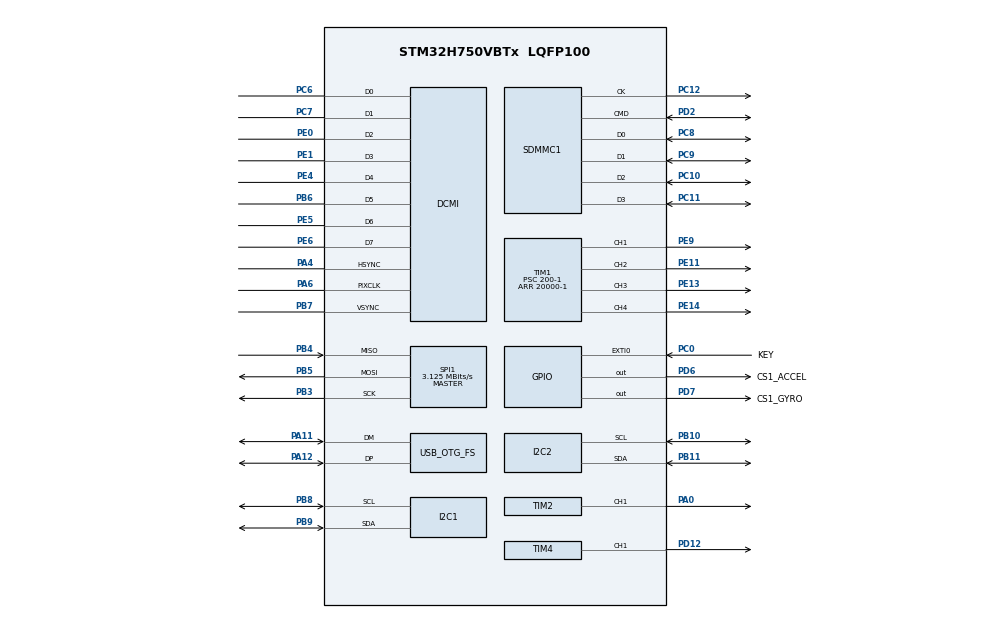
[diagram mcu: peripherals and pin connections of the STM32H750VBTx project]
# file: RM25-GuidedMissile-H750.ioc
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CORTEX_M7.AccessPermission-Cortex_Memory_Protection_Unit_Region0_Settings=MPU_REGION_FULL_ACCESS
CORTEX_M7.BaseAddress-Cortex_Memory_Protection_Unit_Region0_Settings=0x24000000
CORTEX_M7.CPU_DCache=Enabled
CORTEX_M7.CPU_ICache=Enabled
CORTEX_M7.Enable-Cortex_Memory_Protection_Unit_Region0_Settings=MPU_REGION_ENABLE
CORTEX_M7.Enable-Cortex_Memory_Protection_Unit_Region1_Settings=__NULL
CORTEX_M7.Enable-Cortex_Memory_Protection_Unit_Region2_Settings=__NULL
CORTEX_M7.IsBufferable-Cortex_Memory_Protection_Unit_Region0_Settings=MPU_ACCESS_BUFFERABLE
CORTEX_M7.IsCacheable-Cortex_Memory_Protection_Unit_Region0_Settings=MPU_ACCESS_CACHEABLE
CORTEX_M7.IsShareable-Cortex_Memory_Protection_Unit_Region0_Settings=MPU_ACCESS_NOT_SHAREABLE
CORTEX_M7.MPU_Control=MPU_PRIVILEGED_DEFAULT
CORTEX_M7.Size-Cortex_Memory_Protection_Unit_Region0_Settings=MPU_REGION_SIZE_256KB
DCMI.JPEGMode=DCMI_JPEG_DISABLE
Dma.DCMI.0.Direction=DMA_PERIPH_TO_MEMORY
Dma.DCMI.0.EventEnable=DISABLE
Dma.DCMI.0.FIFOMode=DMA_FIFOMODE_ENABLE
Dma.DCMI.0.FIFOThreshold=DMA_FIFO_THRESHOLD_FULL
Dma.DCMI.0.Instance=DMA1_Stream0
Dma.DCMI.0.MemBurst=DMA_MBURST_SINGLE
Dma.DCMI.0.MemDataAlignment=DMA_MDATAALIGN_HALFWORD
Dma.DCMI.0.MemInc=DMA_MINC_ENABLE
Dma.DCMI.0.Mode=DMA_CIRCULAR
Dma.DCMI.0.PeriphBurst=DMA_PBURST_SINGLE
Dma.DCMI.0.PeriphDataAlignment=DMA_PDATAALIGN_WORD
Dma.DCMI.0.PeriphInc=DMA_PINC_DISABLE
Dma.DCMI.0.Polarity=HAL_DMAMUX_REQ_GEN_RISING
Dma.DCMI.0.Priority=DMA_PRIORITY_LOW
Dma.DCMI.0.RequestNumber=1
Dma.DCMI.0.SignalID=NONE
Dma.DCMI.0.SyncEnable=DISABLE
Dma.DCMI.0.SyncPolarity=HAL_DMAMUX_SYNC_NO_EVENT
Dma.DCMI.0.SyncRequestNumber=1
Dma.DCMI.0.SyncSignalID=NONE
Dma.Request0=DCMI
Dma.Request1=TIM2_CH1
Dma.TIM2_CH1.1.Direction=DMA_MEMORY_TO_PERIPH
Dma.TIM2_CH1.1.EventEnable=DISABLE
Dma.TIM2_CH1.1.FIFOMode=DMA_FIFOMODE_DISABLE
Dma.TIM2_CH1.1.Instance=DMA1_Stream1
Dma.TIM2_CH1.1.MemDataAlignment=DMA_MDATAALIGN_WORD
Dma.TIM2_CH1.1.MemInc=DMA_MINC_ENABLE
Dma.TIM2_CH1.1.Mode=DMA_NORMAL
Dma.TIM2_CH1.1.PeriphDataAlignment=DMA_PDATAALIGN_WORD
Dma.TIM2_CH1.1.PeriphInc=DMA_PINC_DISABLE
Dma.TIM2_CH1.1.Polarity=HAL_DMAMUX_REQ_GEN_RISING
Dma.TIM2_CH1.1.Priority=DMA_PRIORITY_LOW
Dma.TIM2_CH1.1.RequestNumber=1
Dma.TIM2_CH1.1.SignalID=NONE
Dma.TIM2_CH1.1.SyncEnable=DISABLE
Dma.TIM2_CH1.1.SyncPolarity=HAL_DMAMUX_SYNC_NO_EVENT
Dma.TIM2_CH1.1.SyncRequestNumber=1
Dma.TIM2_CH1.1.SyncSignalID=NONE
FATFS.USE_DMA_CODE_SD=1
I2C1.Timing=0x10C0ECFF
I2C2.Timing=0x10C0ECFF
Mcu.Family=STM32H7
Mcu.Name=STM32H750VBTx
Mcu.Package=LQFP100
Mdma.MDMA_Channel0.Request0=SDMMC1_END_DATA
Mdma.MDMA_Channel0.RequestsNb=1
Mdma.MDMA_Channel0.SDMMC1_END_DATA.0.BlockCount=0
Mdma.MDMA_Channel0.SDMMC1_END_DATA.0.BlockDataLength=0
Mdma.MDMA_Channel0.SDMMC1_END_DATA.0.BufferTransferLength=1
Mdma.MDMA_Channel0.SDMMC1_END_DATA.0.CircularMode=MDMA_LINEAR_LIST
Mdma.MDMA_Channel0.SDMMC1_END_DATA.0.DataAlignment=MDMA_DATAALIGN_PACKENABLE
Mdma.MDMA_Channel0.SDMMC1_END_DATA.0.DestBlockAddressOffset=0
Mdma.MDMA_Channel0.SDMMC1_END_DATA.0.DestBurst=MDMA_DEST_BURST_SINGLE
Mdma.MDMA_Channel0.SDMMC1_END_DATA.0.DestDataSize=MDMA_DEST_DATASIZE_BYTE
Mdma.MDMA_Channel0.SDMMC1_END_DATA.0.DestinationInc=MDMA_DEST_INC_BYTE
Mdma.MDMA_Channel0.SDMMC1_END_DATA.0.DstAddress=0
Mdma.MDMA_Channel0.SDMMC1_END_DATA.0.Endianness=MDMA_LITTLE_ENDIANNESS_PRESERVE
Mdma.MDMA_Channel0.SDMMC1_END_DATA.0.Instance=MDMA_Channel0
Mdma.MDMA_Channel0.SDMMC1_END_DATA.0.MaskAddress=0
Mdma.MDMA_Channel0.SDMMC1_END_DATA.0.MaskData=0
Mdma.MDMA_Channel0.SDMMC1_END_DATA.0.Priority=MDMA_PRIORITY_VERY_HIGH
Mdma.MDMA_Channel0.SDMMC1_END_DATA.0.Rank=First
Mdma.MDMA_Channel0.SDMMC1_END_DATA.0.SourceBlockAddressOffset=0
Mdma.MDMA_Channel0.SDMMC1_END_DATA.0.SourceBurst=MDMA_SOURCE_BURST_SINGLE
Mdma.MDMA_Channel0.SDMMC1_END_DATA.0.SourceDataSize=MDMA_SRC_DATASIZE_BYTE
Mdma.MDMA_Channel0.SDMMC1_END_DATA.0.SourceInc=MDMA_SRC_INC_BYTE
Mdma.MDMA_Channel0.SDMMC1_END_DATA.0.SrcAddress=0
Mdma.MDMA_Channel0.SDMMC1_END_DATA.0.TransferTriggerMode=MDMA_BUFFER_TRANSFER
Mdma.RequestSet0=MDMA_Channel0
Mdma.RequestSetsNb=1
NVIC.DCMI_IRQn=true\:6\:0\:true\:false\:true\:true\:true\:true
NVIC.DMA1_Stream0_IRQn=true\:7\:0\:true\:false\:true\:false\:true\:true
NVIC.DMA1_Stream1_IRQn=true\:0\:0\:false\:false\:true\:false\:true\:true
NVIC.EXTI0_IRQn=true\:5\:0\:true\:false\:true\:true\:true\:true
NVIC.MDMA_IRQn=true\:8\:0\:true\:false\:true\:true\:true\:true
NVIC.OTG_FS_IRQn=true\:0\:0\:true\:false\:true\:false\:true\:true
NVIC.PriorityGroup=NVIC_PRIORITYGROUP_4
NVIC.SDMMC1_IRQn=true\:9\:0\:true\:false\:true\:true\:true\:true
NVIC.TIM2_IRQn=true\:0\:0\:true\:false\:true\:true\:true\:true
NVIC.TIM6_DAC_IRQn=true\:10\:0\:true\:false\:true\:true\:true\:true
PA0.GPIO_PuPd=GPIO_NOPULL
PA0.GPIO_Speed=GPIO_SPEED_FREQ_VERY_HIGH
PA0.Signal=S_TIM2_CH1_ETR
PA11.Mode=Device_Only
PA11.Signal=USB_OTG_FS_DM
PA12.Mode=Device_Only
PA12.Signal=USB_OTG_FS_DP
PA13\ (JTMS/SWDIO).Mode=Serial_Wire
PA13\ (JTMS/SWDIO).Signal=DEBUG_JTMS-SWDIO
PA14\ (JTCK/SWCLK).Mode=Serial_Wire
PA14\ (JTCK/SWCLK).Signal=DEBUG_JTCK-SWCLK
PA4.Mode=Slave_8_bits_External_Synchro
PA4.Signal=DCMI_HSYNC
PA6.Mode=Slave_8_bits_External_Synchro
PA6.Signal=DCMI_PIXCLK
PB10.GPIO_Pu=GPIO_PULLUP
PB10.Mode=I2C
PB10.Signal=I2C2_SCL
PB11.GPIO_Pu=GPIO_PULLUP
PB11.Mode=I2C
PB11.Signal=I2C2_SDA
PB3\ (JTDO/TRACESWO).GPIO_PuPd=GPIO_PULLUP
PB3\ (JTDO/TRACESWO).GPIO_Speed=GPIO_SPEED_FREQ_MEDIUM
PB3\ (JTDO/TRACESWO).Mode=Full_Duplex_Master
PB3\ (JTDO/TRACESWO).Signal=SPI1_SCK
PB4\ (NJTRST).GPIO_PuPd=GPIO_PULLUP
PB4\ (NJTRST).GPIO_Speed=GPIO_SPEED_FREQ_MEDIUM
PB4\ (NJTRST).Mode=Full_Duplex_Master
PB4\ (NJTRST).Signal=SPI1_MISO
PB5.GPIO_PuPd=GPIO_PULLUP
PB5.GPIO_Speed=GPIO_SPEED_FREQ_MEDIUM
PB5.Mode=Full_Duplex_Master
PB5.Signal=SPI1_MOSI
PB6.Mode=Slave_8_bits_External_Synchro
PB6.Signal=DCMI_D5
PB7.Mode=Slave_8_bits_External_Synchro
PB7.Signal=DCMI_VSYNC
PB8.GPIO_Pu=GPIO_PULLUP
PB8.Mode=I2C
PB8.Signal=I2C1_SCL
PB9.GPIO_Pu=GPIO_PULLUP
PB9.Mode=I2C
PB9.Signal=I2C1_SDA
PC0.GPIO_Label=KEY
PC0.GPIO_ModeDefaultEXTI=GPIO_MODE_IT_RISING_FALLING
PC0.GPIO_PuPd=GPIO_PULLUP
PC0.Signal=GPXTI0
PC10.GPIO_PuPd=GPIO_PULLUP
PC10.Mode=SD_4_bits_Wide_bus
PC10.Signal=SDMMC1_D2
PC11.GPIO_PuPd=GPIO_PULLUP
PC11.Mode=SD_4_bits_Wide_bus
PC11.Signal=SDMMC1_D3
PC12.GPIO_PuPd=GPIO_PULLUP
PC12.GPIO_Speed_High_Default=GPIO_SPEED_FREQ_VERY_HIGH
PC12.Mode=SD_4_bits_Wide_bus
PC12.Signal=SDMMC1_CK
PC6.Mode=Slave_8_bits_External_Synchro
PC6.Signal=DCMI_D0
PC7.Mode=Slave_8_bits_External_Synchro
PC7.Signal=DCMI_D1
PC8.GPIO_PuPd=GPIO_PULLUP
PC8.GPIO_Speed_High_Default=GPIO_SPEED_FREQ_VERY_HIGH
PC8.Mode=SD_4_bits_Wide_bus
PC8.Signal=SDMMC1_D0
PC9.GPIO_PuPd=GPIO_PULLUP
PC9.Mode=SD_4_bits_Wide_bus
PC9.Signal=SDMMC1_D1
PD12.Signal=S_TIM4_CH1
PD14.Signal=S_TIM4_CH3
PD2.GPIO_PuPd=GPIO_PULLUP
PD2.GPIO_Speed_High_Default=GPIO_SPEED_FREQ_VERY_HIGH
PD2.Mode=SD_4_bits_Wide_bus
PD2.Signal=SDMMC1_CMD
PD6.GPIO_Label=CS1_ACCEL
PD6.GPIO_PuPd=GPIO_PULLUP
PD6.Signal=GPIO_Output
PD7.GPIO_Label=CS1_GYRO
PD7.GPIO_PuPd=GPIO_PULLUP
PD7.Signal=GPIO_Output
PE0.Mode=Slave_8_bits_External_Synchro
PE0.Signal=DCMI_D2
PE1.Mode=Slave_8_bits_External_Synchro
PE1.Signal=DCMI_D3
PE11.Signal=S_TIM1_CH2
PE13.Signal=S_TIM1_CH3
PE14.Signal=S_TIM1_CH4
PE4.Mode=Slave_8_bits_External_Synchro
PE4.Signal=DCMI_D4
PE5.Mode=Slave_8_bits_External_Synchro
PE5.Signal=DCMI_D6
PE6.Mode=Slave_8_bits_External_Synchro
PE6.Signal=DCMI_D7
PE9.Signal=S_TIM1_CH1
PH0-OSC_IN\ (PH0).Mode=HSE-External-Oscillator
PH0-OSC_IN\ (PH0).Signal=RCC_OSC_IN
PH1-OSC_OUT\ (PH1).Mode=HSE-External-Oscillator
PH1-OSC_OUT\ (PH1).Signal=RCC_OSC_OUT
ProjectManager.HeapSize=0x2000
ProjectManager.StackSize=0x2000
ProjectManager.TargetToolchain=MDK-ARM V5.32
RCC.ADCFreq_Value=24000000
RCC.APB1Freq_Value=100000000
RCC.APB2Freq_Value=100000000
RCC.APB3Freq_Value=100000000
RCC.APB4Freq_Value=100000000
RCC.CortexFreq_Value=400000000
RCC.D1PPRE=RCC_APB3_DIV2
RCC.D2PPRE1=RCC_APB1_DIV2
RCC.D2PPRE2=RCC_APB2_DIV2
RCC.D3PPRE=RCC_APB4_DIV2
RCC.DIVM1=5
RCC.DIVM2=25
RCC.DIVM3=25
RCC.DIVN1=160
RCC.DIVN2=48
RCC.DIVN3=192
RCC.DIVQ1=4
RCC.DIVQ3=4
RCC.DIVR2=1
RCC.HCLKFreq_Value=200000000
RCC.HPRE=RCC_HCLK_DIV2
RCC.PLL2FRACN=0
RCC.PLL3FRACN=0
RCC.PLLFRACN=0
RCC.PLLSourceVirtual=RCC_PLLSOURCE_HSE
RCC.SYSCLKFreq_VALUE=400000000
RCC.SYSCLKSource=RCC_SYSCLKSOURCE_PLLCLK
RCC.USBCLockSelection=RCC_USBCLKSOURCE_HSI48
RCC.USBFreq_Value=48000000
SDMMC1.ClockDiv=5
SH.S_TIM1_CH1.0=TIM1_CH1,PWM Generation1 CH1
SH.S_TIM1_CH2.0=TIM1_CH2,PWM Generation2 CH2
SH.S_TIM1_CH3.0=TIM1_CH3,PWM Generation3 CH3
SH.S_TIM1_CH4.0=TIM1_CH4,PWM Generation4 CH4
SH.S_TIM2_CH1_ETR.0=TIM2_CH1,PWM Generation1 CH1
SH.S_TIM4_CH1.0=TIM4_CH1,PWM Generation1 CH1
SH.S_TIM4_CH3.0=TIM4_CH3
SPI1.BaudRatePrescaler=SPI_BAUDRATEPRESCALER_64
SPI1.CLKPhase=SPI_PHASE_2EDGE
SPI1.CLKPolarity=SPI_POLARITY_HIGH
SPI1.CalculateBaudRate=3.125 MBits/s
SPI1.DataSize=SPI_DATASIZE_8BIT
SPI1.Direction=SPI_DIRECTION_2LINES
SPI1.Mode=SPI_MODE_MASTER
SPI1.VirtualType=VM_MASTER
TIM1.Channel-PWM\ Generation1\ CH1=TIM_CHANNEL_1
TIM1.Channel-PWM\ Generation2\ CH2=TIM_CHANNEL_2
TIM1.Channel-PWM\ Generation3\ CH3=TIM_CHANNEL_3
TIM1.Channel-PWM\ Generation4\ CH4=TIM_CHANNEL_4
TIM1.Period=20000-1
TIM1.Prescaler=200-1
TIM1.Pulse-PWM\ Generation1\ CH1=2000
TIM1.Pulse-PWM\ Generation2\ CH2=2000
TIM1.Pulse-PWM\ Generation3\ CH3=2000
TIM1.Pulse-PWM\ Generation4\ CH4=2000
TIM2.Channel-PWM\ Generation1\ CH1=TIM_CHANNEL_1
TIM2.Period=250-1
TIM2.Prescaler=0
TIM4.Channel-PWM\ Generation1\ CH1=TIM_CHANNEL_1
TIM6.Period=1000-1
TIM6.Prescaler=200-1
USB_DEVICE.CLASS_NAME_FS=CDC
USB_DEVICE.VirtualMode-CDC_FS=Cdc
USB_DEVICE.VirtualModeFS=Cdc_FS
USB_OTG_FS.VirtualMode=Device_Only
VP_FATFS_VS_SDIO.Mode=SDIO
VP_TIM1_VS_ClockSourceINT.Mode=Internal
VP_TIM2_VS_ClockSourceINT.Mode=Internal
VP_TIM4_VS_ClockSourceINT.Mode=Internal
VP_TIM6_VS_ClockSourceINT.Mode=Enable_Timer
VP_USB_DEVICE_VS_USB_DEVICE_CDC_FS.Mode=CDC_FS
board=custom

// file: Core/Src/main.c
/* USER CODE BEGIN Header */
/**
  ******************************************************************************
  * @file           : main.c
  * @brief          : Main program body
  ******************************************************************************
  * @attention
  *
  * Copyright (c) 2023 STMicroelectronics.
  * All rights reserved.
  *
  * This software is licensed under terms that can be found in the LICENSE file
  * in the root directory of this software component.
  * If no LICENSE file comes with this software, it is provided AS-IS.
  *
  ******************************************************************************
  */
/* USER CODE END Header */
#include "main.h"
#include "dcmi.h"
#include "dma.h"
#include "fatfs.h"
#include "i2c.h"
#include "mdma.h"
#include "sdmmc.h"
#include "spi.h"
#include "tim.h"
#include "usb_device.h"
#include "gpio.h"

/* USER CODE BEGIN Includes */
#include "missile.h"
/* USER CODE END Includes */

void SystemClock_Config(void);
static void MPU_Initialize(void);
static void MPU_Config(void);

int main(void)
{

  /* Enable I-Cache---------------------------------------------------------*/
  SCB_EnableICache();

  /* Enable D-Cache---------------------------------------------------------*/
  SCB_EnableDCache();

  /* MCU Configuration--------------------------------------------------------*/

  /* Reset of all peripherals, Initializes the Flash interface and the Systick. */
  HAL_Init();

  /* MPU Configuration--------------------------------------------------------*/
  MPU_Config();

  /* Configure the system clock */
  SystemClock_Config();

  /* Initialize all configured peripherals */
  MX_GPIO_Init();
  MX_DMA_Init();
  MX_MDMA_Init();
  MX_TIM6_Init();
  MX_FATFS_Init();
  MX_DCMI_Init();
  MX_USB_DEVICE_Init();
  MX_I2C1_Init();
  MX_TIM1_Init();
  MX_SDMMC1_SD_Init();
  MX_SPI1_Init();
  MX_TIM2_Init();
  MX_I2C2_Init();
  MX_TIM4_Init();
  /* USER CODE BEGIN 2 */
  controlInit();
  /* USER CODE END 2 */

  /* Infinite loop */
  /* USER CODE BEGIN WHILE */
  while (1)
  {
    controlWhileLoop();
    /* USER CODE END WHILE */

  }
}

void SystemClock_Config(void)
{
  RCC_OscInitTypeDef RCC_OscInitStruct = {0};
  RCC_ClkInitTypeDef RCC_ClkInitStruct = {0};

  /** Supply configuration update enable
  */
  HAL_PWREx_ConfigSupply(PWR_LDO_SUPPLY);

  /** Configure the main internal regulator output voltage
  */
  __HAL_PWR_VOLTAGESCALING_CONFIG(PWR_REGULATOR_VOLTAGE_SCALE1);

  while(!__HAL_PWR_GET_FLAG(PWR_FLAG_VOSRDY)) {}

  /** Initializes the RCC Oscillators according to the specified parameters
  * in the RCC_OscInitTypeDef structure.
  */
  RCC_OscInitStruct.OscillatorType = RCC_OSCILLATORTYPE_HSI48|RCC_OSCILLATORTYPE_HSE;
  RCC_OscInitStruct.HSEState = RCC_HSE_ON;
  RCC_OscInitStruct.HSI48State = RCC_HSI48_ON;
  RCC_OscInitStruct.PLL.PLLState = RCC_PLL_ON;
  RCC_OscInitStruct.PLL.PLLSource = RCC_PLLSOURCE_HSE;
  RCC_OscInitStruct.PLL.PLLM = 5;
  RCC_OscInitStruct.PLL.PLLN = 160;
  RCC_OscInitStruct.PLL.PLLP = 2;
  RCC_OscInitStruct.PLL.PLLQ = 4;
  RCC_OscInitStruct.PLL.PLLR = 2;
  RCC_OscInitStruct.PLL.PLLRGE = RCC_PLL1VCIRANGE_2;
  RCC_OscInitStruct.PLL.PLLVCOSEL = RCC_PLL1VCOWIDE;
  RCC_OscInitStruct.PLL.PLLFRACN = 0;
  if (HAL_RCC_OscConfig(&RCC_OscInitStruct) != HAL_OK)
  {
    Error_Handler();
  }

  /** Initializes the CPU, AHB and APB buses clocks
  */
  RCC_ClkInitStruct.ClockType = RCC_CLOCKTYPE_HCLK|RCC_CLOCKTYPE_SYSCLK
                              |RCC_CLOCKTYPE_PCLK1|RCC_CLOCKTYPE_PCLK2
                              |RCC_CLOCKTYPE_D3PCLK1|RCC_CLOCKTYPE_D1PCLK1;
  RCC_ClkInitStruct.SYSCLKSource = RCC_SYSCLKSOURCE_PLLCLK;
  RCC_ClkInitStruct.SYSCLKDivider = RCC_SYSCLK_DIV1;
  RCC_ClkInitStruct.AHBCLKDivider = RCC_HCLK_DIV2;
  RCC_ClkInitStruct.APB3CLKDivider = RCC_APB3_DIV2;
  RCC_ClkInitStruct.APB1CLKDivider = RCC_APB1_DIV2;
  RCC_ClkInitStruct.APB2CLKDivider = RCC_APB2_DIV2;
  RCC_ClkInitStruct.APB4CLKDivider = RCC_APB4_DIV2;

  if (HAL_RCC_ClockConfig(&RCC_ClkInitStruct, FLASH_LATENCY_2) != HAL_OK)
  {
    Error_Handler();
  }
}

/* MPU Configuration */

void MPU_Config(void)
{
  MPU_Region_InitTypeDef MPU_InitStruct = {0};

  /* Disables the MPU */
  HAL_MPU_Disable();

  /** Initializes and configures the Region and the memory to be protected
  */
  MPU_InitStruct.Enable = MPU_REGION_ENABLE;
  MPU_InitStruct.Number = MPU_REGION_NUMBER0;
  MPU_InitStruct.BaseAddress = 0x24000000;
  MPU_InitStruct.Size = MPU_REGION_SIZE_256KB;
  MPU_InitStruct.SubRegionDisable = 0x0;
  MPU_InitStruct.TypeExtField = MPU_TEX_LEVEL0;
  MPU_InitStruct.AccessPermission = MPU_REGION_FULL_ACCESS;
  MPU_InitStruct.DisableExec = MPU_INSTRUCTION_ACCESS_ENABLE;
  MPU_InitStruct.IsShareable = MPU_ACCESS_NOT_SHAREABLE;
  MPU_InitStruct.IsCacheable = MPU_ACCESS_CACHEABLE;
  MPU_InitStruct.IsBufferable = MPU_ACCESS_BUFFERABLE;

  HAL_MPU_ConfigRegion(&MPU_InitStruct);
  /* Enables the MPU */
  HAL_MPU_Enable(MPU_PRIVILEGED_DEFAULT);

}

void Error_Handler(void)
{
  __disable_irq();
  while (1)
  {
  }
}
